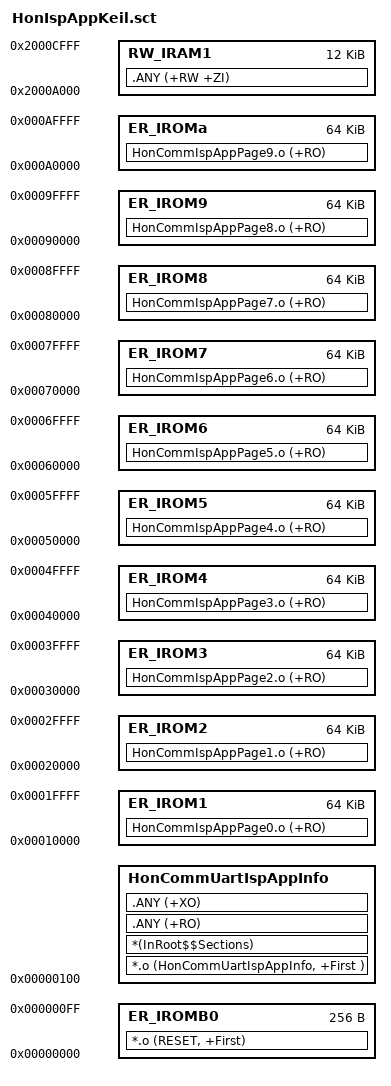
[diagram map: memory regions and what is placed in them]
; *************************************************************
; *** Scatter-Loading Description File generated by uVision ***
; *************************************************************
LR_IROMB0 0x00000000 0x100  {    ; load region size_region
  ER_IROMB0 0x00000000 0x100  {  ; load address = execution address
   *.o (RESET, +First)
  }
}
LR_IROMB1 0x00000100 0xFF00  {    ; load region size_region
  HonCommUartIspAppInfo  0x00000100  {  ; load address = execution address
   *.o (HonCommUartIspAppInfo, +First )
   *(InRoot$$Sections)
   .ANY (+RO)
   .ANY (+XO)
  }
  RW_IRAM1 0x2000A000 0x3000  {  ; RW data
   .ANY (+RW +ZI)
  }
}
LR_IROM1 0x00010000 0x10000  {    ; load region size_region
  ER_IROM1 0x00010000 0x10000  {  ; load address = execution address
   HonCommIspAppPage0.o (+RO)
  }
}
LR_IROM2 0x00020000 0x10000  {    ; load region size_region
  ER_IROM2 0x00020000 0x10000  {  ; load address = execution address
   HonCommIspAppPage1.o (+RO)
  }
}
LR_IROM3 0x00030000 0x10000  {    ; load region size_region
  ER_IROM3 0x00030000 0x10000  {  ; load address = execution address
   HonCommIspAppPage2.o (+RO)
  }
}
LR_IROM4 0x00040000 0x10000  {    ; load region size_region
  ER_IROM4 0x00040000 0x10000  {  ; load address = execution address
   HonCommIspAppPage3.o (+RO)
  }
}
LR_IROM5 0x00050000 0x10000  {    ; load region size_region
  ER_IROM5 0x00050000 0x10000  {  ; load address = execution address
   HonCommIspAppPage4.o (+RO)
  }
}
LR_IROM6 0x00060000 0x10000  {    ; load region size_region
  ER_IROM6 0x00060000 0x10000  {  ; load address = execution address
   HonCommIspAppPage5.o (+RO)
  }
}
LR_IROM7 0x00070000 0x10000  {    ; load region size_region
  ER_IROM7 0x00070000 0x10000  {  ; load address = execution address
   HonCommIspAppPage6.o (+RO)
  }
}
LR_IROM8 0x00080000 0x10000  {    ; load region size_region
  ER_IROM8 0x00080000 0x10000  {  ; load address = execution address
   HonCommIspAppPage7.o (+RO)
  }
}
LR_IROM9 0x00090000 0x10000  {    ; load region size_region
  ER_IROM9 0x00090000 0x10000  {  ; load address = execution address
   HonCommIspAppPage8.o (+RO)
  }
}
LR_IROMa 0x000a0000 0x10000  {    ; load region size_region
  ER_IROMa 0x000a0000 0x10000  {  ; load address = execution address
   HonCommIspAppPage9.o (+RO)
  }
}





